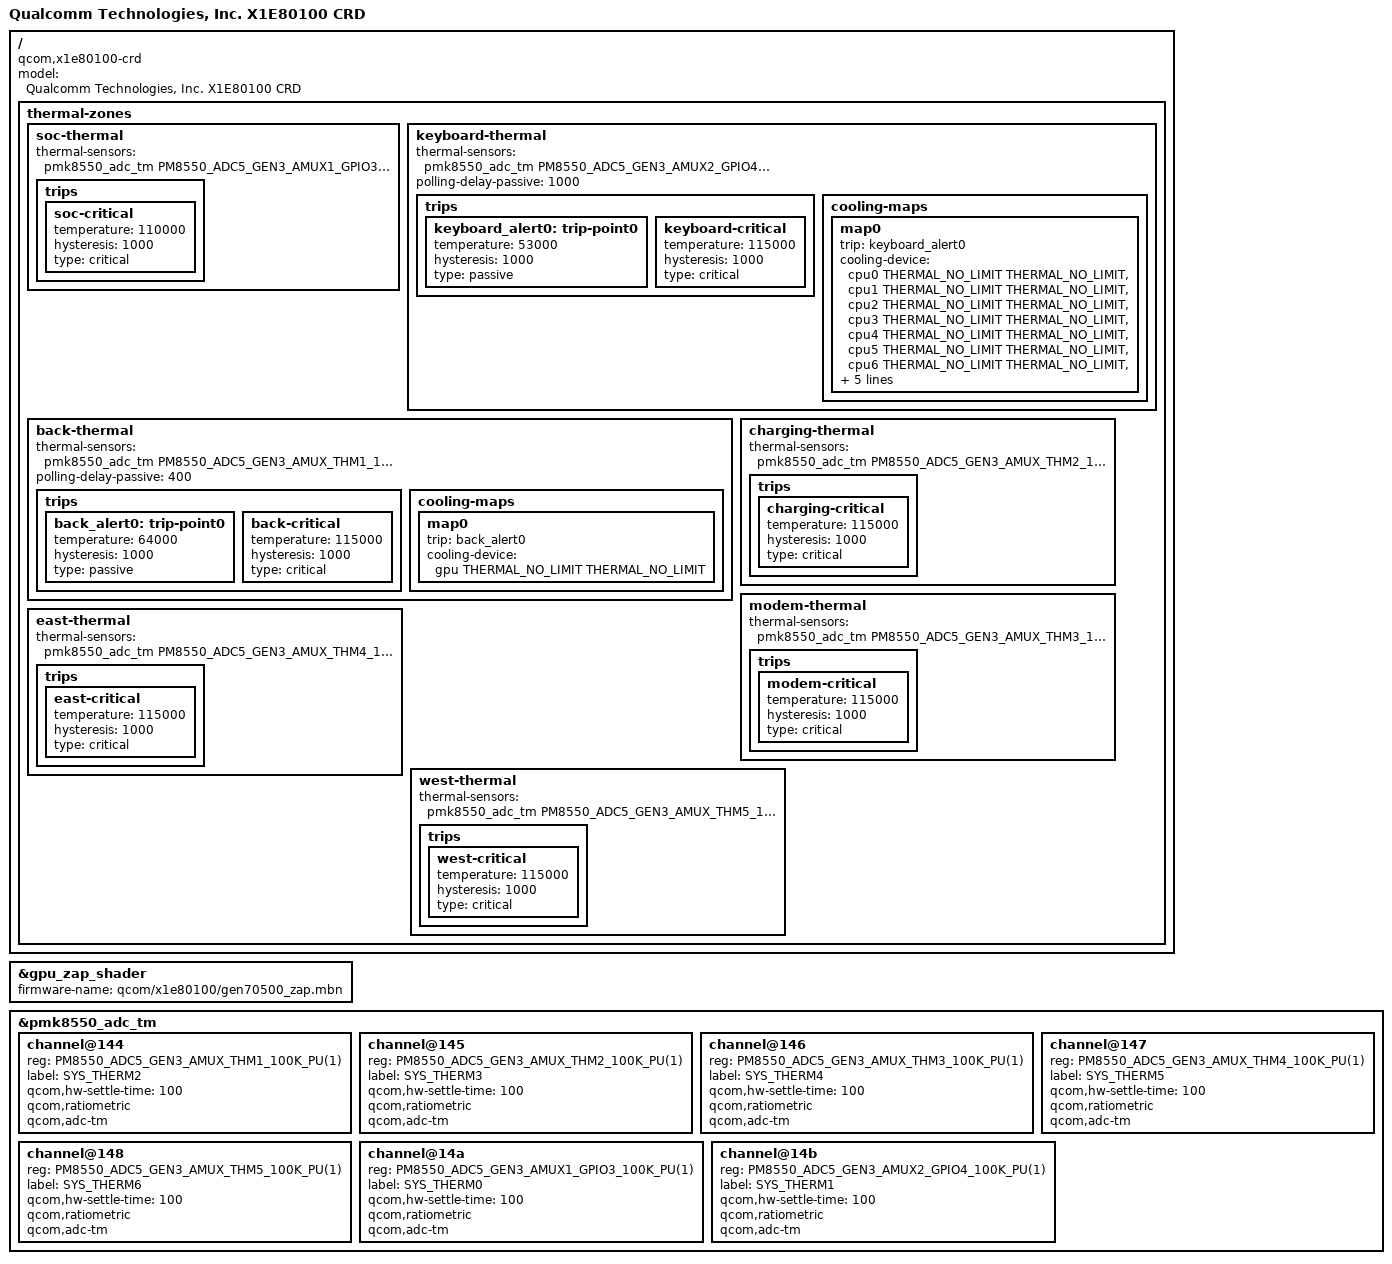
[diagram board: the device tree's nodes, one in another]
// SPDX-License-Identifier: BSD-3-Clause
/*
 * Copyright (c) 2023 Qualcomm Innovation Center, Inc. All rights reserved.
 */

/dts-v1/;

#include "x1e80100.dtsi"
#include "x1-crd.dtsi"

/ {
	model = "Qualcomm Technologies, Inc. X1E80100 CRD";
	compatible = "qcom,x1e80100-crd", "qcom,x1e80100";

	thermal-zones {
		soc-thermal {
			thermal-sensors = <&pmk8550_adc_tm PM8550_ADC5_GEN3_AMUX1_GPIO3_100K_PU(1)>;

			trips {
				soc-critical {
					temperature = <110000>;
					hysteresis = <1000>;
					type = "critical";
				};
			};
		};

		keyboard-thermal {
			thermal-sensors = <&pmk8550_adc_tm PM8550_ADC5_GEN3_AMUX2_GPIO4_100K_PU(1)>;
			polling-delay-passive = <1000>;

			trips {
				keyboard_alert0: trip-point0 {
					temperature = <53000>;
					hysteresis = <1000>;
					type = "passive";
				};

				keyboard-critical {
					temperature = <115000>;
					hysteresis = <1000>;
					type = "critical";
				};
			};

			cooling-maps {
				map0 {
					trip = <&keyboard_alert0>;
					cooling-device = <&cpu0 THERMAL_NO_LIMIT THERMAL_NO_LIMIT>,
							 <&cpu1 THERMAL_NO_LIMIT THERMAL_NO_LIMIT>,
							 <&cpu2 THERMAL_NO_LIMIT THERMAL_NO_LIMIT>,
							 <&cpu3 THERMAL_NO_LIMIT THERMAL_NO_LIMIT>,
							 <&cpu4 THERMAL_NO_LIMIT THERMAL_NO_LIMIT>,
							 <&cpu5 THERMAL_NO_LIMIT THERMAL_NO_LIMIT>,
							 <&cpu6 THERMAL_NO_LIMIT THERMAL_NO_LIMIT>,
							 <&cpu7 THERMAL_NO_LIMIT THERMAL_NO_LIMIT>,
							 <&cpu8 THERMAL_NO_LIMIT THERMAL_NO_LIMIT>,
							 <&cpu9 THERMAL_NO_LIMIT THERMAL_NO_LIMIT>,
							 <&cpu10 THERMAL_NO_LIMIT THERMAL_NO_LIMIT>,
							 <&cpu11 THERMAL_NO_LIMIT THERMAL_NO_LIMIT>;
				};
			};
		};

		back-thermal {
			thermal-sensors = <&pmk8550_adc_tm PM8550_ADC5_GEN3_AMUX_THM1_100K_PU(1)>;
			polling-delay-passive = <400>;

			trips {
				back_alert0: trip-point0 {
					temperature = <64000>;
					hysteresis = <1000>;
					type = "passive";
				};

				back-critical {
					temperature = <115000>;
					hysteresis = <1000>;
					type = "critical";
				};
			};

			cooling-maps {
				map0 {
					trip = <&back_alert0>;
					cooling-device = <&gpu THERMAL_NO_LIMIT THERMAL_NO_LIMIT>;
				};
			};
		};

		charging-thermal {
			thermal-sensors = <&pmk8550_adc_tm PM8550_ADC5_GEN3_AMUX_THM2_100K_PU(1)>;

			trips {
				charging-critical {
					temperature = <115000>;
					hysteresis = <1000>;
					type = "critical";
				};
			};
		};

		modem-thermal {
			thermal-sensors = <&pmk8550_adc_tm PM8550_ADC5_GEN3_AMUX_THM3_100K_PU(1)>;

			trips {
				modem-critical {
					temperature = <115000>;
					hysteresis = <1000>;
					type = "critical";
				};
			};
		};

		east-thermal {
			thermal-sensors = <&pmk8550_adc_tm PM8550_ADC5_GEN3_AMUX_THM4_100K_PU(1)>;

			trips {
				east-critical {
					temperature = <115000>;
					hysteresis = <1000>;
					type = "critical";
				};
			};
		};

		west-thermal {
			thermal-sensors = <&pmk8550_adc_tm PM8550_ADC5_GEN3_AMUX_THM5_100K_PU(1)>;

			trips {
				west-critical {
					temperature = <115000>;
					hysteresis = <1000>;
					type = "critical";
				};
			};
		};
	};
};

&gpu_zap_shader {
	firmware-name = "qcom/x1e80100/gen70500_zap.mbn";
};

&pmk8550_adc_tm {
	channel@144 {
		reg = <PM8550_ADC5_GEN3_AMUX_THM1_100K_PU(1)>;
		label = "SYS_THERM2";
		qcom,hw-settle-time = <100>;
		qcom,ratiometric;
		qcom,adc-tm;
	};
	channel@145 {
		reg = <PM8550_ADC5_GEN3_AMUX_THM2_100K_PU(1)>;
		label = "SYS_THERM3";
		qcom,hw-settle-time = <100>;
		qcom,ratiometric;
		qcom,adc-tm;
	};
	channel@146 {
		reg = <PM8550_ADC5_GEN3_AMUX_THM3_100K_PU(1)>;
		label = "SYS_THERM4";
		qcom,hw-settle-time = <100>;
		qcom,ratiometric;
		qcom,adc-tm;
	};
	channel@147 {
		reg = <PM8550_ADC5_GEN3_AMUX_THM4_100K_PU(1)>;
		label = "SYS_THERM5";
		qcom,hw-settle-time = <100>;
		qcom,ratiometric;
		qcom,adc-tm;
	};
	channel@148 {
		reg = <PM8550_ADC5_GEN3_AMUX_THM5_100K_PU(1)>;
		label = "SYS_THERM6";
		qcom,hw-settle-time = <100>;
		qcom,ratiometric;
		qcom,adc-tm;
	};
	channel@14a {
		reg = <PM8550_ADC5_GEN3_AMUX1_GPIO3_100K_PU(1)>;
		label = "SYS_THERM0";
		qcom,hw-settle-time = <100>;
		qcom,ratiometric;
		qcom,adc-tm;
	};
	channel@14b {
		reg = <PM8550_ADC5_GEN3_AMUX2_GPIO4_100K_PU(1)>;
		label = "SYS_THERM1";
		qcom,hw-settle-time = <100>;
		qcom,ratiometric;
		qcom,adc-tm;
	};
};
